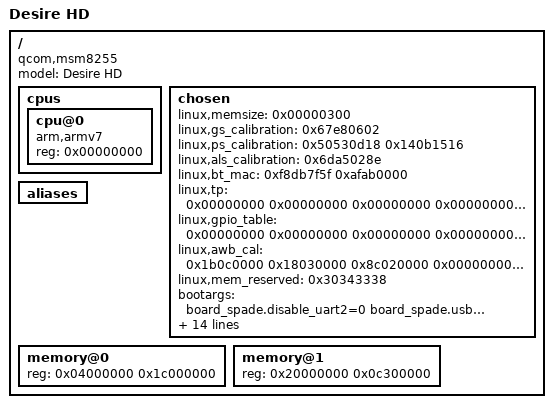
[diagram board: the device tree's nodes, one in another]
/dts-v1/;
// magic:		0xd00dfeed
// totalsize:		0x23bf (9151)
// off_dt_struct:	0x38
// off_dt_strings:	0x2234
// off_mem_rsvmap:	0x28
// version:		17
// last_comp_version:	16
// boot_cpuid_phys:	0x0
// size_dt_strings:	0x18b
// size_dt_struct:	0x21fc

/ {
    model = "Desire HD";
    compatible = "qcom,msm8255";
    #address-cells = <0x00000001>;
    #size-cells = <0x00000001>;
    cpus {
        #address-cells = <0x00000001>;
        #size-cells = <0x00000000>;
        cpu@0 {
            device_type = "cpu";
            compatible = "arm,armv7";
            reg = <0x00000000>;
        };
    };
    chosen {
        linux,memsize = <0x00000300>;
        linux,gs_calibration = <0x67e80602>;
        linux,ps_calibration = <0x50530d18 0x140b1516>;
        linux,als_calibration = <0x6da5028e>;
        linux,bt_mac = <0xf8db7f5f 0xafab0000>;
        linux,tp = <0x00000000 0x00000000 0x00000000 0x00000000 0x00000000 0x00000000 0x00000000 0x00000000>;
        linux,gpio_table = <0x00000000 0x00000000 0x00000000 0x00000000 0x00000000 0x00000000 0x00000000 0x00000000 0x00000000 0x00000000 0x00000000 0x00000000 0x00000000 0x00000000 0x00000000 0x00000000 0x00000000 0x00000000 0x00000000 0x00000000 0x00000000 0x00000000 0x00000000 0x00000000 0x00000000 0x00000000 0x00000000 0x00000000 0x00000000 0x00000000 0x00000000 0x00000000 0x00000000 0x00000000 0x00000000 0x00000000 0x00000000 0x00000000 0x00000000 0x00000000 0x00000000 0x00000000 0x00000000 0x00000000 0x00000000 0x00000000 0x00000000 0x00000000 0x00000000 0x00000000 0x00000000 0x00000000 0x00000000 0x00000000 0x00000000 0x00000000 0x00000000 0x00000000 0x00000000 0x00000000 0x00000000 0x00000000 0x00000000 0x00000000 0x00000000 0x00000000 0x00000000 0x00000000 0x00000000 0x00000000 0x00000000 0x00000000 0x00000000 0x00000000 0x00000000 0x00000000 0x00000000 0x00000000 0x00000000 0x00000000 0x00000000 0x00000000 0x00000000 0x00000000 0x00000000 0x00000000 0x00000000 0x00000000 0x00000000 0x00000000 0x00000000 0x00000000 0x00000000 0x00000000 0x00000000 0x00000000 0x00000000 0x00000000 0x00000000 0x00000000 0x00000000 0x00000000 0x00000000 0x00000000 0x00000000 0x00000000 0x00000000 0x00000000 0x00000000 0x00000000 0x00000000 0x00000000 0x00000000 0x00000000 0x00000000 0x00000000 0x00000000 0x00000000 0x00000000 0x00000000 0x00000000 0x00000000 0x00000000 0x00000000 0x00000000 0x00000000 0x00000000 0x00000000 0x00000000 0x00000000 0x00000000 0x00000000 0x00000000 0x00000000 0x00000000 0x00000000 0x00000000 0x00000000 0x00000000 0x00000000 0x00000000 0x00000000 0x00000000 0x00000000 0x00000000 0x00000000 0x00000000 0x00000000 0x00000000 0x00000000 0x00000000 0x00000000 0x00000000 0x00000000 0x00000000 0x00000000 0x00000000 0x00000000 0x00000000 0x00000000 0x00000000 0x00000000 0x00000000 0x00000000 0x00000000 0x00000000 0x00000000 0x00000000 0x00000000 0x00000000 0x00000000 0x00000000 0x00000000 0x00000000 0x00000000 0x00000000 0x00000000 0x00000000 0x00000000 0x00000000 0x00000000 0x00000000 0x00000000 0x00000000 0x00000000 0x00000000 0x00000000 0x00000000 0x00000000 0x00000000 0x00000000 0x00000000 0x00000000 0x00000000 0x00000000 0x00000000 0x00000000 0x00000000 0x00000000 0x00000000 0x00000000 0x00000000 0x00000000 0x00000000 0x00000000 0x00000000 0x00000000 0x00000000 0x00000000 0x00000000 0x00000000 0x00000000 0x00000000 0x00000000 0x00000000 0x00000000 0x00000000 0x00000000 0x00000000 0x00000000 0x00000000 0x00000000 0x00000000 0x00000000 0x00000000 0x00000000 0x00000000 0x00000000 0x00000000 0x00000000 0x00000000 0x00000000 0x00000000 0x00000000 0x00000000 0x00000000 0x00000000 0x00000000 0x00000000 0x00000000 0x00000000 0x00000000 0x00000000 0x00000000 0x00000000 0x00000000 0x00000000 0x00000000 0x00000000 0x00000000 0x00000000 0x00000000 0x00000000 0x00000000 0x00000000 0x00000000>;
        linux,awb_cal = <0x1b0c0000 0x18030000 0x8c020000 0x00000000 0x00000000 0x04000000 0x4579ca00 0xb648a8e2 0x1b0c0000 0x00000000 0x00000000 0x04000000 0x4579ca00 0x11740640 0x78c2fa3f 0xf380e63f 0xa2e2d73f 0xdeefcd3f 0xbb19c83f 0x1d88c33f 0xec41c03f 0x1717c03f 0x81fdc13f 0x3d9ac43f 0xfb5aca3f 0x3869d23f 0xa518df3f 0x1b1cf43f 0x763e0740 0x3fae1540 0xc044f93f 0x11feea3f 0x768fd93f 0x97e2c83f 0xecadbf3f 0xe99cb83f 0x6f27b33f 0xf9d3b03f 0x62c1ad3f 0xfc3fb03f 0x5c56b43f 0x9201bb3f 0x46f0c43f 0x14c4d13f 0x4d40e33f 0xc460fe3f 0xa5150b40 0xcf7ce93f 0xc61edc3f 0xa31bc93f 0x615bbb3f 0xf7e9b03f 0x75f1a83f 0x1893a23f 0xb0029f3f 0x2baf9d3f 0x3f1f9f3f 0x4012a33f 0x824dab3f 0x1e43b73f 0xa259c43f 0xea25d63f 0x6bddeb3f 0x92fe0140 0x3761dc3f 0x16bfcd3f 0x96a1be3f 0xedb2b03f 0x1fa5a43f 0xbf629b3f 0xf35d953f 0xa969913f 0x3861903f 0xa055923f 0x90d4963f 0x4f6e9f3f 0x6fb7ab3f 0x5818bc3f 0x3a42cc3f 0x1ab4e13f 0xd307f83f 0x6606d53f 0x3aa0c73f 0x4ae9b53f 0xc8eea63f 0xc32b9b3f 0x0ffa913f 0x1bd98b3f 0x40d3883f 0x00a4873f 0x9964893f 0xc5c78d3f 0x37ff963f 0x8856a33f 0x6ea6b23f 0x565bc63f 0x3828db3f 0x120def3f 0x6e8ed03f 0x0361c23f 0x0132b13f 0xde5da23f 0x780a953f 0x32948c3f 0x5d8c863f 0xf17b833f 0x0502823f 0xb3c8843f 0x775d893f 0x9a6b933f 0xe6819f3f 0x2813b03f 0xb1d9c23f 0x05a7d63f 0x96e9ed3f 0x8531cf3f 0xd12ec23f 0x8aafb03f 0x3081a13f 0x05c1943f 0x1f818b3f 0xb9d1843f 0x491e823f 0x229a813f 0xde1c843f 0x5044893f 0x9bb1923f 0x514b9f3f 0x92baaf3f 0xaa4bc33f 0xab2ed93f 0xe44def3f 0x33cfd43f 0x7bc3c33f 0xa012b23f 0xe3c9a23f 0xd74d973f 0xf4c08d3f 0x1cfa863f 0x5d11843f 0x20a0843f 0x64c8863f 0x28808c3f 0x4f80963f 0xfd35a33f 0x9c70b53f 0xc9a0c83f 0x00bede3f 0x6d00f43f 0x8479d83f 0x9a3dca3f 0xc7a1b63f 0x33d3a83f 0xd3729d3f 0x8016933f 0xab718d3f 0xa98d8b3f 0x1e878a3f 0x0b338d3f 0xd992923f 0x88be9c3f 0x065daa3f 0x3f0fbc3f 0xdc91cf3f 0xd544e53f 0x64d2fe3f 0xa525e43f 0x2309d33f 0xc674bf3f 0xea4bb23f 0x4b9fa63f 0xf1489e3f 0x00f8963f 0x4ed7953f 0xff14953f 0x48a9963f 0xeb869d3f 0x3074a73f 0x2814b53f 0x314fc63f 0x431bd93f 0x4b6cf03f 0xba790540 0x3259f33f 0x40a6e33f 0x9196ce3f 0x9098be3f 0x6ddbb33f 0x806aac3f 0x0f88a53f 0xd73ea33f 0xf13ba43f 0x41a7a63f 0xfb98ac3f 0x9867b63f 0xcda7c33f 0x6f13d43f 0x4a4ae73f 0x979d0040 0x94780e40 0xd2400540 0x3097f73f 0x5436e13f 0x26aecf3f 0xf43cc63f 0x229cbd3f 0x4744b83f 0x6c77b63f 0x3699b63f 0xa855b93f 0x5418bf3f 0xef91c83f 0xf5b4d33f 0x1a86e53f 0x73a8fa3f 0xcb9e0940 0x3d001b40 0x3bed1740 0x908f0940 0x0efdf73f 0x26c5e53f 0x1950db3f 0x5607d33f 0x96b8ce3f 0x6154cd3f 0xbc9ecd3f 0x7649d03f 0xad03d63f 0x5609de3f 0x82afe93f 0x8823fc3f 0xf73c0a40 0xf7d41940 0x2c8e3340 0xe9020140 0x9b81ec3f 0xaaafdd3f 0x85eed03f 0x37b0c73f 0x9c33c33f 0xb2b8bf3f 0x7825bc3f 0x6d42bb3f 0xbb47bc3f 0xb09abe3f 0x496bc13f 0x1b82c83f 0xc293d23f 0x0eb8e13f 0xa8f1f83f 0x126c0a40 0x7b4cf13f 0x5d9fdf3f 0xe37ccf3f 0x6d62c43f 0x91c2bb3f 0x8a11b63f 0xd7bcb03f 0x057cad3f 0x0232ad3f 0xbfabac3f 0xa559b03f 0x2de0b53f 0x82edbc3f 0xf1a5c63f 0x0a48d43f 0x60aee93f 0xa1200040 0x616ee23f 0x8489d13f 0xe259c23f 0xb196b83f 0x8286b03f 0x7d19a83f 0x3fe8a13f 0xcd299d3f 0xd5699c3f 0xa8b59d3f 0x7b03a13f 0x3e2aa83f 0x7abdb13f 0x4604bb3f 0x446fc93f 0x7d05dc3f 0x8259f03f 0x6259d83f 0x0910c73f 0xa165ba3f 0x8e07af3f 0x2f70a43f 0x0b929b3f 0x57f0933f 0xb2a5903f 0x6203903f 0x31d8903f 0x5830963f 0x72e39c3f 0xb7a9a73f 0x16d3b33f 0x7048c13f 0x56d2d13f 0x6925e73f 0xbe0dd03f 0x00a2bf3f 0x7c32b23f 0xd72ba63f 0x29789a3f 0xe77b923f 0xc8588b3f 0x0641873f 0xda93863f 0x7839893f 0x671d8e3f 0xa75d963f 0x9ee7a03f 0x638aae3f 0x8132bd3f 0xc84acc3f 0xa378e13f 0x6b2fce3f 0x61aebb3f 0x8fe7af3f 0xc880a13f 0x57f5963f 0x39ac8d3f 0x3ab9863f 0x1f44833f 0x8fbe823f 0x8121853f 0x16ae8a3f 0x2fa1923f 0x5b699e3f 0x75ddac3f 0x67babc3f 0x98fbca3f 0x0db5df3f 0x2c3acc3f 0x6796ba3f 0xb875ad3f 0x52e6a03f 0xc97b953f 0xd5e28b3f 0x10e8843f 0x0255823f 0x0de1813f 0x2e68843f 0x2c708a3f 0x3d02933f 0xaeaa9e3f 0x2454ac3f 0xaffebc3f 0x8793cc3f 0xde5de23f 0x4506ce3f 0xf6eabc3f 0xe3fbae3f 0xf63fa23f 0x75ab973f 0x23328e3f 0xadf7863f 0xf753843f 0xacf1843f 0xc731883f 0x4f8f8d3f 0x39a4963f 0x3c8fa13f 0xdb31b23f 0xf7a9c03f 0x9571d13f 0xfd3ae63f 0x5c00d43f 0x1da8c13f 0x35dab33f 0xccd5a73f 0x8ed79c3f 0x0f60943f 0xe8708e3f 0xdaa48a3f 0xa9128b3f 0x32b18e3f 0x71f2933f 0x67759d3f 0x3b71a93f 0x4c2db83f 0x392bc73f 0x0922d83f 0x8cb6f03f 0x6b6ede3f 0xcefeca3f 0x3018bb3f 0xd5e1af3f 0x8340a73f 0xcbd89d3f 0x3a1d983f 0x6aca943f 0x5934963f 0xada6993f 0x92229f3f 0x3ccfa73f 0xf505b33f 0x3c45c13f 0x25a9cf3f 0xf74ce13f 0x5bf2fd3f 0xd61ced3f 0x3234d93f 0x7530c63f 0x1c70bb3f 0x0dd9b13f 0x3229aa3f 0x0a7ba43f 0x2c0ca33f 0x3404a33f 0x0b04a73f 0x15a6ac3f 0x0e33b53f 0x7e0bc03f 0xc289cc3f 0xbf2ddb3f 0x9a97f13f 0xe46e0740 0x8aaa0040 0xdb27eb3f 0xf177d73f 0x9165c83f 0xbf2ec03f 0x4f03ba3f 0x2d3cb53f 0x2f5bb33f 0x2fa3b23f 0xb54bb83f 0x4e00be3f 0xf04ec53f 0x5146ce3f 0xa1addb3f 0x49c2ed3f 0x11130240 0x33521340 0x8c0a1540 0xf2dc0340 0xe524ef3f 0xc100df3f 0xd1e2d43f 0xc0cacb3f 0x61e6c93f 0x70c4c73f 0xcacac83f 0x12a5cc3f 0x266dd03f 0x6920d93f 0xec97e43f 0xaee7f33f 0x82220340 0x03b71140 0xfe5e2a40 0xa43a0040 0x6afce73f 0xbce7d53f 0xfc79cb3f 0x6946c13f 0x92e5bd3f 0x195cbb3f 0x381bb93f 0x56caba3f 0x0f2fbd3f 0x7739c03f 0x5164c73f 0x0624cf3f 0x662fda3f 0xffd9eb3f 0x1d840240 0xd6b91040 0x3416ee3f 0x3270dc3f 0x7e41ca3f 0x4b59bd3f 0xf261b73f 0xa9c7b03f 0xd2caad3f 0xf4bdab3f 0x883fac3f 0x02edae3f 0x86fab23f 0x871fba3f 0xa19ac33f 0x3359cd3f 0xd629dd3f 0x8c4af43f 0x30780440 0xbb93e03f 0x1382cb3f 0x42ecbc3f 0x1801b33f 0x6461ab3f 0xf73aa33f 0xc7409e3f 0xc3259c3f 0x269c9b3f 0xf1139e3f 0x6723a43f 0xd7d2ab3f 0xde2cb63f 0x73dac23f 0xcb20cf3f 0xdd14e43f 0x9d14fa3f 0xce71d53f 0x8cb1c23f 0x61adb43f 0x5582ab3f 0x86d4a03f 0x36ee983f 0xe880923f 0x9e618f3f 0x36348f3f 0x8001923f 0x12b3973f 0x9390a03f 0x9512ac3f 0x35f3b93f 0x3e9ec83f 0x22ebd83f 0x0f3eee3f 0x2587cf3f 0xb60fbe3f 0x6dfcb03f 0x80ffa33f 0x2ced983f 0x5294903f 0x58268a3f 0x4955863f 0x4877863f 0x0c4f893f 0x27508e3f 0xf47f983f 0x3c08a43f 0x802fb23f 0x8368c13f 0x9319d23f 0x6bd4e53f 0x0acacc3f 0x7883bb3f 0xedfbad3f 0x7008a13f 0x551f953f 0x2b268c3f 0xce5a853f 0x779d813f 0x686e823f 0x9fc6843f 0x2ce08a3f 0xa463943f 0x939aa03f 0x8a9eae3f 0x567abe3f 0x6ea4ce3f 0xa87ce33f 0xdfc8cd3f 0x95f1bb3f 0xb76dad3f 0x3004a23f 0x3e99953f 0xb9fa8a3f 0x9950853f 0x0562813f 0xc1b2813f 0x4b7f843f 0x55208a3f 0x1a61933f 0x17209f3f 0xf7ddad3f 0xc64dbe3f 0xc9e0cc3f 0xe226e43f 0x8e1dd23f 0x31bebf3f 0xcc8ab23f 0x303aa53f 0x5a64993f 0x922c8f3f 0x1320883f 0xd294843f 0x6a0c843f 0x5651873f 0xec0d8d3f 0x124d963f 0xf82da23f 0x5314b13f 0x2908c13f 0xe0e1d03f 0xf01ce63f 0x44afd83f 0xd63fc73f 0x7cbcb63f 0x6cb5aa3f 0xd984a03f 0x0bb1963f 0xcaf48e3f 0x93608b3f 0x82ee893f 0x53ef8c3f 0xb78e923f 0x1e6a9b3f 0xb156a83f 0x2511b63f 0x8bdfc43f 0xa46fd53f 0xb51bef3f 0xbfe8e33f 0xc308d03f 0x984dc03f 0xcc82b53f 0x8421aa3f 0xedf4a03f 0xbb9c993f 0xab49953f 0xddb6943f 0x5eac963f 0xa1bb9d3f 0xc314a63f 0x475eb13f 0xb6a5bd3f 0xa104cb3f 0x4a52df3f 0xe958f73f 0x13fdf43f 0x710ae03f 0x6945ce3f 0xcc61c03f 0xb445b63f 0x9eddaf3f 0x529ba73f 0x3ddda33f 0xdfdfa23f 0x07c6a53f 0xaac6a93f 0x7ba2b33f 0xc5e0bd3f 0x51ecc83f 0xe576d73f 0x93c4eb3f 0x45df0340 0x47040640 0x37a1f13f 0xee21df3f 0x90afd13f 0xc2d8c63f 0xb739bf3f 0xa610b93f 0x0d2ab63f 0xef25b53f 0x0dffb53f 0x8e11bb3f 0x6353c23f 0x469ac93f 0x8261d73f 0x693ae73f 0x00c1fd3f 0xbf5b0f40 0x241e1940 0x70ce0540 0xcd6af63f 0x76efe53f 0x86e6db3f 0x1b4cd43f 0x930dcd3f 0xd288ca3f 0x9420c93f 0x0973c93f 0xf20ece3f 0xd513d53f 0x355edd3f 0x8464eb3f 0x3320fe3f 0xfbaf0b40 0xea242340 0x64f7e03f 0x92b4d43f 0x98b7c63f 0xaae7bd3f 0xbb76b73f 0x933eb43f 0x8f8db33f 0x83b5b23f 0xd283b43f 0xe59cb63f 0x7f46b93f 0x2bfebc3f 0x0d8dc33f 0xc38fcc3f 0xf5d4db3f 0xbfddf13f 0x66800440 0x8a85d23f 0x2de8c83f 0x8a7abc3f 0x5ceab23f 0x07a2af3f 0xbea2aa3f 0xbf9ea83f 0x0e57a73f 0x64bca73f 0x70caa93f 0x2d53ad3f 0x5907b23f 0x3d5fb93f 0x9fefc13f 0x4bdbce3f 0x72b5e33f 0x4e34f43f 0xc8bac43f 0x987cbc3f 0x5970b03f 0x1fa3a93f 0xdc61a43f 0x56269e3f 0x87e89a3f 0x7bc09a3f 0xb0689a3f 0x2fa59c3f 0x2dfe9f3f 0xcb8ca63f 0xda65ad3f 0x0f6cb63f 0x90bbc23f 0xa2d0d23f 0xa9d3e33f 0xcfbabb3f 0xa265b23f 0x3842a93f 0x07bea13f 0x30419a3f 0x53e3943f 0x25db903f 0xad0b8f3f 0x4e808f3f 0xaf1f913f 0x8d1a963f 0xaeb19c3f 0x3d21a43f 0xa09aaf3f 0x3c75bb3f 0x8cdcc83f 0x22e1d83f 0x91f5b53f 0x3242ac3f 0x456ca43f 0x677d9b3f 0xd312933f 0x04fb8d3f 0xf14e893f 0x0f8d873f 0xa743873f 0xe46e893f 0x594f8d3f 0x0d45933f 0x03db9c3f 0x0a6da83f 0xd1dfb33f 0x63a1c03f 0xca1dd23f 0x3553b33f 0x0998aa3f 0xde4fa13f 0x10d4973f 0xccbb8f3f 0x92a5893f 0xc852853f 0x081b833f 0x7bf5823f 0xc23a853f 0x7493883f 0xa646903f 0x1edd983f 0x566ea43f 0x56efb03f 0xb2d4bd3f 0x6e9dcd3f 0xcb4bb43f 0xd135ab3f 0x4db0a13f 0xd81c983f 0x98be8f3f 0xfc3d893f 0xadd7843f 0x3c9f823f 0xec7b823f 0x9dfd833f 0x542a883f 0x2c028f3f 0xb72c983f 0x1afda33f 0xc45ab03f 0x3b2cbd3f 0xf345cd3f 0x8822b73f 0xd73aaf3f 0xdf64a43f 0x9bae9a3f 0xb7f2913f 0xa14e8c3f 0x30fa863f 0x9c13853f 0x0904853f 0xddac873f 0x44e28a3f 0x7be6913f 0x977e9b3f 0x4be5a53f 0x0278b23f 0xc17cbe3f 0x70bacd3f 0xcd00bd3f 0x81afb43f 0x78f8a83f 0xc47aa13f 0x339b983f 0xec6c923f 0xbc038e3f 0x1f108c3f 0x50bd8a3f 0x29708d3f 0x5129903f 0x3c24973f 0xe4b29f3f 0x4eb6aa3f 0x75a0b63f 0x8cd4c23f 0x3df9d33f 0x2855c83f 0x77f0be3f 0x323cb33f 0x9b73aa3f 0xd6d9a23f 0xc87c9c3f 0xd858973f 0x7d13963f 0x15e0943f 0x4038973f 0x4b389a3f 0xe24aa13f 0xb8baa83f 0x342ab23f 0x2652bd3f 0xaf8bca3f 0x2802de3f 0xd5f9d53f 0xb019cc3f 0xf659bf3f 0xfeb9b43f 0xc560ae3f 0xd495a93f 0xd348a53f 0xb234a23f 0xcda1a13f 0xa5ada33f 0xa2cca63f 0xd97ead3f 0x8b56b23f 0x1bf4bb3f 0x1cb1c73f 0xe618d73f 0xa36bed3f 0x7477e93f 0x224cdd3f 0x9eafcf3f 0x1020c33f 0xfb45bc3f 0xb2b5b73f 0x8f39b53f 0xfd15b23f 0x1adcb23f 0x9210b33f 0x568db53f 0xdc20ba3f 0x744abf3f 0x533dc93f 0x9e93d73f 0x0386e93f 0xb0920040 0x97bf0440 0x5c77f23f 0xe12ae23f 0xcc46d53f 0x24bfcc3f 0x020ec63f 0x63c8c43f 0x863ec23f 0xb4b8c03f 0xd4c9c13f 0xabaec33f 0x7dc7c73f 0xfff4cf3f 0xc3b5da3f 0x72c3e83f 0xc2c3fe3f 0xe84a1440 0xae24eac8 0x00000000 0x00000000 0x00000000 0x00000000 0x00000000 0x00000000 0x00000000 0x00000000 0x00000000 0x00000000 0x00000000 0x00000000 0x00000000 0x00000000 0x00000000 0x00000000 0x00000000 0x00000000 0x00000000 0x00000000 0x00000000 0x00000000 0x00000000 0x00000000 0x00000000 0x00000000 0x00000000 0x00000000 0x00000000 0x00000000 0x00000000 0x00000000 0x00000000 0x00000000 0x00000000 0x00000000 0x00000000 0x00000000 0x00000000 0x00000000 0x00000000 0x00000000 0x00000000 0x00000000 0x00000000 0x00000000 0x00000000 0x00000000 0x00000000 0x00000000 0x00000000 0x00000000 0x00000000 0x00000000 0x00000000 0x00000000 0x00000000 0x00000000 0x00000000 0x00000000 0x00000000 0x00000000 0x00000000 0x00000000 0x00000000 0x00000000 0x00000000 0x00000000 0x00000000 0x00000000 0x00000000 0x00000000 0x00000000 0x00000000 0x00000000 0x00000000 0x00000000 0x00000000 0x00000000 0x00000000 0x00000000 0x00000000 0x00000000 0x00000000 0x00000000 0x00000000 0x00000000 0x00000000 0x00000000 0x00000000 0x00000000 0x00000000 0x00000000 0x00000000 0x00000000 0x00000000 0x00000000 0x00000000 0x00000000 0x00000000 0x00000000 0x00000000 0x00000000 0x00000000 0x00000000 0x00000000 0x00000000 0x00000000 0x00000000 0x00000000 0x00000000 0x00000000 0x00000000 0x00000000 0x00000000 0x00000000 0x00000000 0x00000000 0x00000000 0x00000000 0x00000000 0x00000000 0x00000000 0x00000000 0x00000000 0x00000000>;
        linux,mem_reserved = <0x30343338>;
        bootargs = "board_spade.disable_uart2=0 board_spade.usb_h2w_sw=0 board_spade.disable_sdcard=0 diag.enabled=0 board_spade.debug_uart=0 smisize=0 userdata_sel=0 androidboot.emmc=true  androidboot.baseband=26.13.04.19_M androidboot.cid=HTC__001 androidboot.batt_poweron=good_battery androidboot.carrier=HTC-WWE androidboot.mid=PD9810000 androidboot.keycaps=qwerty androidboot.mode=normal androidboot.serialno=xxxxxxxxxxxx androidboot.bootloader=0.85.2007 g_ffs.idVendor=15d9, g_ffs.idProduct=0a4d no_console_suspend=1 androidboot.selinux=permissive androidboot.hardware=htc7x30";
        linux,initrd-end = <0x050d0a03>;
        linux,initrd-start = <0x05000000>;
        linux,engineerid = <0x00000000>;
        linux,smi = <0x00000000>;
        linux,hwid = <0x00000000>;
        linux,skuid = <0x00026503>;
        linux,panel_type = <0x00000000>;
        linux,revision = <0x00000080 0x00000080>;
        linux,wifi = <0x2943ee00 0x02000000 0x03000000 0x0d030000 0xcfac9ebd 0x00000000 0x00000000 0x00000000 0x00000000 0x30000000 0x00000000 0x00000000 0x00000000 0x00000000 0x00000000 0x00000000 0x6d616361 0x6464723d 0x46383a44 0x423a3746 0x3a34443a 0x41463a43 0x310d0a73 0x726f6d72 0x65763d33 0x0d0a7665 0x6e646964 0x3d307831 0x3465340d 0x0a646576 0x69643d30 0x78343332 0x660d0a62 0x6f617264 0x74797065 0x3d307834 0x62390d0a 0x626f6172 0x64726576 0x3d307833 0x360d0a62 0x6f617264 0x666c6167 0x733d3078 0x3230300d 0x0a787461 0x6c667265 0x713d3337 0x3430300d 0x0a616132 0x673d310d 0x0a616135 0x673d300d 0x0a616730 0x3d323535 0x0d0a7061 0x3062303d 0x35353134 0x2c353531 0x342c3535 0x39330d0a 0x70613062 0x313d3634 0x3235372c 0x36343235 0x372c3634 0x3238370d 0x0a706130 0x62323d36 0x35323833 0x2c363532 0x38332c36 0x35333238 0x0d0a7061 0x30697473 0x7369743d 0x36320d0a 0x7061306d 0x61787077 0x723d3734 0x0d0a6f66 0x646d706f 0x3d307838 0x38383838 0x3838360d 0x0a6d6373 0x3267706f 0x303d3078 0x41414141 0x0d0a6d63 0x73326770 0x6f313d30 0x78414141 0x410d0a72 0x73736973 0x6d663267 0x3d307861 0x2c307861 0x2c307861 0x0d0a7273 0x7369736d 0x6332673d 0x3078622c 0x3078622c 0x3078610d 0x0a727373 0x69736176 0x32673d30 0x78332c30 0x78332c30 0x78330d0a 0x7263616c 0x5f666c61 0x673d3078 0x36310d0a 0x62786132 0x673d300d 0x0a63636f 0x64653d41 0x4c4c0d0a 0x6363746c 0x3d307830 0x0d0a6363 0x6b646967 0x66696c74 0x74797065 0x3d300d0a 0x6f66646d 0x64696766 0x696c7474 0x7970653d 0x310d0a72 0x78706f32 0x673d300d 0x0a626f61 0x72646e75 0x6d3d310d 0x0a6e6f63 0x72633d31 0x0d0a6f74 0x70696d61 0x67657369 0x7a653d31 0x38320d0a 0x68776864 0x723d3078 0x30356666 0x66663033 0x31303330 0x30333130 0x30333130 0x30303030 0x0d0a5241 0x57313d38 0x30203332 0x20666520 0x32312030 0x32203063 0x20303020 0x32322032 0x61203031 0x20303120 0x30302030 0x30206335 0x20302065 0x36203030 0x20303020 0x30302030 0x30203030 0x20343020 0x30302030 0x30206666 0x20666620 0x38302030 0x30203030 0x20303020 0x30302030 0x30203030 0x20303020 0x30302030 0x30203030 0x20633820 0x30302030 0x30203030 0x20303020 0x30302030 0x30203030 0x20303020 0x30302030 0x30203030 0x20303020 0x30302066 0x66203230 0x20303420 0x44302032 0x20323920 0x34332032 0x31203032 0x20306320 0x30302032 0x32203034 0x20303020 0x32302030 0x30203541 0x0d0a7364 0x5f67706f 0x75743d30 0x0d0a7364 0x5f6f6f62 0x6f6e6c79 0x3d310d0a 0x00000000 0x00000000 0x00000000 0x00000000 0x00000000 0x00000000 0x00000000 0x00000000 0x00000000 0x00000000 0x00000000 0x00000000 0x00000000 0x00000000 0x00000000 0x00000000 0x00000000 0x00000000 0x00000000 0x00000000 0x00000000 0x00000000 0x00000000 0x00000000 0x00000000 0x00000000 0x00000000 0x00000000 0x00000000 0x00000000 0x00000000 0x00000000 0x00000000 0x00000000 0x00000000 0x00000000 0x00000000 0x00000000 0x00000000 0x00000000 0x00000000 0x00000000 0x00000000 0x00000000 0x00000000 0x00000000 0x00000000 0x00000000 0x00000000 0x00000000 0x00000000 0x00000000 0x00000000 0x00000000 0x00000000 0x00000000 0x00000000 0x00000000 0x00000000 0x00000000 0x00000000 0x00000000 0x00000000 0x00000000 0x00000000 0x00000000 0x00000000 0x00000000 0x00000000 0x00000000 0x00000000 0x00000000 0x00000000 0x00000000 0x00000000 0x00000000 0x00000000 0x00000000 0x00000000 0x00000000 0x00000000 0x00000000 0x00000000 0x00000000 0x00000000 0x00000000 0x00000000 0x00000000 0x00000000 0x00000000 0x00000000 0x00000000 0x00000000 0x00000000 0x00000000 0x00000000 0x00000000 0x00000000 0x00000000 0x00000000 0x00000000 0x00000000 0x00000000 0x00000000 0x00000000 0x00000000 0x00000000 0x00000000 0x00000000 0x00000000 0x00000000 0x00000000 0x00000000 0x00000000 0x00000000 0x00000000 0x00000000 0x00000000 0x00000000 0x00000000 0x00000000 0x00000000 0x00000000 0x00000000 0x00000000 0x00000000 0x00000000 0x00000000 0x00000000 0x00000000 0x00000000 0x00000000 0x00000000 0x00000000 0x00000000 0x00000000 0x00000000 0x00000000 0x00000000 0x00000000 0x00000000 0x00000000 0x00000000 0x00000000 0x00000000 0x00000000 0x00000000 0x00000000 0x00000000 0x00000000 0x00000000 0x00000000 0x00000000 0x00000000 0x00000000 0x00000000 0x00000000 0x00000000 0x00000000 0x00000000 0x00000000 0x00000000 0x00000000 0x00000000 0x00000000 0x00000000 0x00000000 0x00000000 0x00000000 0x00000000 0x00000000 0x00000000 0x00000000 0x00000000 0x00000000 0x00000000 0x00000000 0x00000000 0x00000000 0x00000000 0x00000000 0x00000000 0x00000000 0x00000000 0x00000000 0x00000000 0x00000000 0x00000000 0x00000000 0x00000000 0x00000000 0x00000000 0x00000000 0x00000000 0x00000000 0x00000000 0x00000000 0x00000000 0x00000000 0x00000000 0x00000000 0x00000000 0x00000000 0x00000000 0x00000000 0x00000000 0x00000000 0x00000000 0x00000000 0x00000000 0x00000000 0x00000000 0x00000000 0x00000000 0x00000000 0x00000000 0x00000000 0x00000000 0x00000000 0x00000000 0x00000000 0x00000000 0x00000000 0x00000000 0x00000000 0x00000000 0x00000000 0x00000000 0x00000000 0x00000000 0x00000000 0x00000000 0x00000000 0x00000000 0x00000000 0x00000000 0x00000000 0x00000000 0x00000000 0x00000000 0x00000000 0x00000000 0x00000000 0x00000000 0x00000000 0x00000000 0x00000000 0x00000000 0x00000000 0x00000000 0x00000000 0x00000000 0x00000000 0x00000000 0x00000000 0x00000000 0x00000000 0x00000000 0x00000000 0x00000000 0x00000000 0x00000000 0x00000000 0x00000000 0x00000000 0x00000000 0x00000000 0x00000000 0x00000000 0x00000000 0x00000000 0x00000000 0x00000000 0x00000000 0x00000000 0x00000000 0x00000000 0x00000000 0x00000000 0x00000000 0x00000000 0x00000000 0x00000000 0x00000000 0x00000000 0x00000000 0x00000000 0x00000000 0x00000000 0x00000000 0x00000000 0x00000000 0x00000000 0x00000000 0x00000000 0x00000000 0x00000000 0x00000000 0x00000000 0x00000000 0x00000000>;
        linux,msm_partitions = <0x6d697363 0x00000000 0x00000000 0x00000000 0x11000000 0x00020000 0x00000000 0x7265636f 0x76657279 0x00000000 0x00000000 0x15000000 0xfa430000 0x00000000 0x626f6f74 0x00000000 0x00000000 0x00000000 0x16000000 0x00200000 0x00000000 0x73797374 0x656d0000 0x00000000 0x00000000 0x19000000 0xff6f1100 0x00000000 0x63616368 0x65000000 0x00000000 0x00000000 0x1b000000 0xff5f0900 0x00000000 0x75736572 0x64617461 0x00000000 0x00000000 0x1a000000 0xffb72400 0x00000000 0x6465766c 0x6f670000 0x00000000 0x00000000 0x1c000000 0xffa50000 0x00000000 0x70646174 0x61000000 0x00000000 0x00000000 0x1d000000 0x00020000 0x00000000>;
        linux,ps_type = <0x00000000>;
        linux,pcbid = <0x00000000>;
    };
    aliases {
    };
    memory@0 {
        device_type = "memory";
        reg = <0x04000000 0x1c000000>;
    };
    memory@1 {
        device_type = "memory";
        reg = <0x20000000 0x0c300000>;
    };
};
